VERSION ""

NS_ :

BS_:

BU_: GNSSReceiver
VAL_TABLE_ evPgn 129029 "GNSS Position Data" 129025 "Position Rapid Update" ;

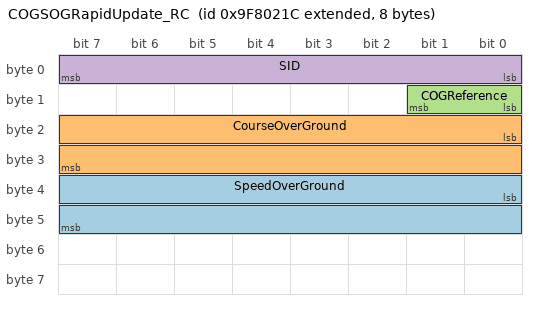
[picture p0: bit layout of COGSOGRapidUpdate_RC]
BO_ 2314732060 COGSOGRapidUpdate_RC: 8 GNSSReceiver
 SG_ SpeedOverGround : 32|16@1+ (0.01,0) [0|655.32] "m/s" Vector__XXX
 SG_ CourseOverGround : 16|16@1+ (0.0001,0) [0|6.28318] "rad" Vector__XXX
 SG_ COGReference : 8|2@1+ (1,0) [0|3] "" Vector__XXX
 SG_ SID : 0|8@1+ (1,0) [0|252] "" Vector__XXX

BO_ 2314731804 GNSSPositionRapidUpdate_RC: 8 GNSSReceiver
 SG_ Latitude : 0|32@1- (1E-007,0) [-90|90] "deg" Vector__XXX
 SG_ Longitude : 32|32@1- (1E-007,0) [-180|180] "deg" Vector__XXX

BO_ 2583168284 GNSSPositionData_RC: 47 GNSSReceiver
 SG_ SequenceID : 0|8@1+ (1,0) [0|255] "" Vector__XXX
 SG_ PositionDate : 8|16@1+ (1,0) [0|65532] "day" Vector__XXX
 SG_ PositionTime : 24|32@1+ (0.0001,0) [0|86401] "s" Vector__XXX
 SG_ Latitude : 56|64@1+ (1E-016,0) [-90|90] "deg" Vector__XXX
 SG_ Longitude : 120|64@1- (1E-016,0) [-180|180] "deg" Vector__XXX
 SG_ Altitude : 184|64@1- (1E-006,0) [-9223372036854.78|9223372036854.78] "m" Vector__XXX
 SG_ TypeOfSystem : 248|4@1+ (1,0) [0|4] "" Vector__XXX
 SG_ GNSSMethod : 252|4@1+ (1,0) [0|15] "" Vector__XXX
 SG_ GNSSIntegrity : 256|2@1+ (1,0) [0|3] "" Vector__XXX
 SG_ NumberOfSVs : 264|8@1+ (1,0) [0|252] "" Vector__XXX
 SG_ HDOP : 272|16@1- (0.01,0) [-327.64|327.64] "" Vector__XXX
 SG_ PDOP : 288|16@1- (0.01,0) [-327.64|327.64] "" Vector__XXX
 SG_ GeoidalSeparation : 304|32@1- (0.01,0) [-21470000|21470000] "m" Vector__XXX
 SG_ NumberOfReferenceStations : 336|8@1+ (1,0) [0|252] "" Vector__XXX
 SG_ RefrenceStationType1 : 344|4@1+ (1,0) [0|15] "" Vector__XXX
 SG_ ReferenceStationID1 : 348|12@1+ (1,0) [0|4095] "" Vector__XXX
 SG_ AgeOfDGNSSCorrections1 : 360|16@1+ (0.01,0) [0|655.32] "sec" Vector__XXX

BO_ 2565799452 ACL_RC: 8 GNSSReceiver
 SG_ IdentityNumber : 0|21@1+ (1,0) [0|2097150] "" Vector__XXX
 SG_ ManufacturerCode : 21|11@1+ (1,0) [0|2047] "" Vector__XXX
 SG_ ECUInstance : 32|3@1+ (1,0) [0|7] "" Vector__XXX
 SG_ FunctionInstance : 35|5@1+ (1,0) [0|31] "" Vector__XXX
 SG_ Function : 40|8@1+ (1,0) [0|255] "" Vector__XXX
 SG_ VehicleSystem1 m1 : 49|7@1+ (1,0) [0|127] "" Vector__XXX
 SG_ VehicleSystem2 m2 : 49|7@1+ (1,0) [0|127] "" Vector__XXX
 SG_ VehicleSystem3 m3 : 49|7@1+ (1,0) [0|127] "" Vector__XXX
 SG_ VehicleSystem4 m4 : 49|7@1+ (1,0) [0|127] "" Vector__XXX
 SG_ VehicleSystem5 m5 : 49|7@1+ (1,0) [0|127] "" Vector__XXX
 SG_ VehicleSystem m0 : 49|7@1+ (1,0) [0|127] "" Vector__XXX
 SG_ VehicleSystemInstance : 56|4@1+ (1,0) [0|15] "" Vector__XXX
 SG_ IndustryGroup M : 60|3@1+ (1,0) [0|7] "" Vector__XXX
 SG_ ArbitraryAddressCapable : 63|1@1+ (1,0) [0|1] "" Vector__XXX

BO_ 2565406236 ACKM_RC: 8 GNSSReceiver
 SG_ ControlByte M : 0|8@1+ (1,0) [0|0] "" Vector__XXX
 SG_ GroupFunctionValue : 8|8@1+ (1,0) [0|0] "" Vector__XXX
 SG_ AddressAcknowledged m0 : 32|8@1+ (1,0) [0|0] "" Vector__XXX
 SG_ AddressNegativeAcknowledgement m1 : 32|8@1+ (1,0) [0|0] "" Vector__XXX
 SG_ AddressAccessDenied m2 : 32|8@1+ (1,0) [0|0] "" Vector__XXX
 SG_ AddressBusy m3 : 32|8@1+ (1,0) [0|0] "" Vector__XXX
 SG_ ParameterGroupNumber : 40|24@1+ (1,0) [0|0] "" Vector__XXX

EV_ evDataNumOfRefStat: 0 [0|252] "" 0 1 DUMMY_NODE_VECTOR0 Vector__XXX;

EV_ evCmdOpenGNSSPosDataValues: 0 [0|1] "" 0 2 DUMMY_NODE_VECTOR0 Vector__XXX;

EV_ evDataGeoSeparation: 0 [-21470000|21470000] "" 0 3 DUMMY_NODE_VECTOR0 Vector__XXX;

EV_ evDataPDOP: 0 [-32764|32764] "" 0 4 DUMMY_NODE_VECTOR0 Vector__XXX;

EV_ evDataHDOP: 0 [-32764|32764] "" 0 5 DUMMY_NODE_VECTOR0 Vector__XXX;

EV_ evDataNumOfSVs: 0 [0|252] "" 0 6 DUMMY_NODE_VECTOR0 Vector__XXX;

EV_ evDataIntegrity: 0 [0|3] "" 0 7 DUMMY_NODE_VECTOR0 Vector__XXX;

EV_ evDataSysAndMethod: 0 [0|255] "" 0 8 DUMMY_NODE_VECTOR0 Vector__XXX;

EV_ evDataFixId: 0 [0|1] "" 0 9 DUMMY_NODE_VECTOR0 Vector__XXX;

EV_ evCmdSetGNSSPosDataValues: 0 [0|1] "" 0 10 DUMMY_NODE_VECTOR0 Vector__XXX;

EV_ evCmdContinueSpeed: 0 [0|1] "" 0 11 DUMMY_NODE_VECTOR0 Vector__XXX;

EV_ evSpeedNew: 1 [0|0] "" 0 12 DUMMY_NODE_VECTOR0 Vector__XXX;

EV_ evAddSpeed: 0 [0|1] "" 0 13 DUMMY_NODE_VECTOR0 Vector__XXX;

EV_ evCmdRemoveWPs: 0 [0|1] "" 0 14 DUMMY_NODE_VECTOR0 Vector__XXX;

EV_ evPGEnable: 0 [0|1] "" 0 15 DUMMY_NODE_VECTOR0 Vector__XXX;

EV_ evCmdSetPGSettings: 0 [0|1] "" 0 16 DUMMY_NODE_VECTOR0 Vector__XXX;

EV_ evPGN: 0 [0|0] "" 129029 17 DUMMY_NODE_VECTOR0 Vector__XXX;

EV_ evPGPriority: 0 [0|7] "" 3 18 DUMMY_NODE_VECTOR0 Vector__XXX;

EV_ evPGUpateRate: 0 [50|100000] "" 1000 19 DUMMY_NODE_VECTOR0 Vector__XXX;

EV_ evJitterAtl: 1 [0|3.4E+038] "" 0 20 DUMMY_NODE_VECTOR0 Vector__XXX;

EV_ evJitterLonLat: 1 [0|3.4E+038] "" 0 21 DUMMY_NODE_VECTOR0 Vector__XXX;

EV_ evCmdPauseSpeed: 0 [0|1] "" 0 22 DUMMY_NODE_VECTOR0 Vector__XXX;

EV_ evSimulationState: 0 [0|2] "" 0 23 DUMMY_NODE_VECTOR0 Vector__XXX;

EV_ evSpeed: 1 [0|1000] "" 0 24 DUMMY_NODE_VECTOR0 Vector__XXX;

EV_ evCmdStopReplay: 0 [0|1] "" 0 25 DUMMY_NODE_VECTOR0 Vector__XXX;

EV_ evCmdStartReplay: 0 [0|1] "" 0 26 DUMMY_NODE_VECTOR0 Vector__XXX;

EV_ evReferenceType: 0 [0|1] "" 0 27 DUMMY_NODE_VECTOR0 Vector__XXX;

EV_ evLengthAltitude: 1 [-3.4E+038|3.4E+038] "" 0 28 DUMMY_NODE_VECTOR0 Vector__XXX;

EV_ evLengthLongitude: 1 [-3.4E+038|3.4E+038] "" 0 29 DUMMY_NODE_VECTOR0 Vector__XXX;

EV_ evLengthLatitude: 1 [-3.4E+038|3.4E+038] "" 0 30 DUMMY_NODE_VECTOR0 Vector__XXX;

EV_ evCmdAddRefPoint: 0 [0|1] "" 0 31 DUMMY_NODE_VECTOR0 Vector__XXX;

EV_ evCmdAddNewPointRef: 0 [0|1] "" 0 32 DUMMY_NODE_VECTOR0 Vector__XXX;

EV_ evCmdAddNewPoint: 0 [0|1] "" 0 33 DUMMY_NODE_VECTOR0 Vector__XXX;

EV_ evAltitudeNew: 1 [-3.4E+038|3.4E+038] "" 0 34 DUMMY_NODE_VECTOR0 Vector__XXX;

EV_ evLongitudeNew: 1 [-180|180] "" 0 35 DUMMY_NODE_VECTOR0 Vector__XXX;

EV_ evLatitudeNew: 1 [-90|90] "" 0 36 DUMMY_NODE_VECTOR0 Vector__XXX;

EV_ evAltitudeRef: 1 [-3.4E+038|3.4E+038] "" 0 37 DUMMY_NODE_VECTOR0 Vector__XXX;

EV_ evLongitudeRef: 1 [-180|180] "" 0 38 DUMMY_NODE_VECTOR0 Vector__XXX;

EV_ evLatitudeRef: 1 [-90|90] "" 0 39 DUMMY_NODE_VECTOR0 Vector__XXX;

CM_ BO_ 2314732060 "This PGN is a single frame PGN that provides Course Over Ground(COG)and Speed Over Ground(SOG).

Being a single frame Msg,as opposed to other PGNs that include COG and SOG and are defined as multi-packet,this PGN lends itself to being transmitted more f";
CM_ SG_ 2314732060 CourseOverGround "The direction of the path over ground actually followed by a vessel.";
CM_ SG_ 2314732060 COGReference "0 = True, 
1 = Magnetic, 
2 = Error, 
3 = Null";
CM_ SG_ 2314732060 SID "An upward counting number used to tie related information together between different PGNs.For example,SID would be used to tie together COG,SOG and RAIM values to a given Pos.255=no valid Pos fix to tie it to.Range 0 to 250 for valid Pos fixes.";
CM_ BO_ 2314731804 "This PGN provides latitude and longitude referenced to WGS84";
CM_ BO_ 2583168284 "This PGN conveys a comprehensive set of Global Navigation Satellite System (GNSS) parameters, including position 
information
";
CM_ SG_ 2583168284 SequenceID "An upward counting number used to tie related information together between different PGNs.
";
CM_ SG_ 2583168284 PositionDate "Days since January 1, 1970,  Date is relative to UTC Time";
CM_ SG_ 2583168284 PositionTime "24 hour clock, 0 =  midnight,  time is in UTC";
CM_ SG_ 2583168284 Latitude "Latitude referenced to WGS-84";
CM_ SG_ 2583168284 Longitude "Longitude referenced to WGS-84";
CM_ SG_ 2583168284 Altitude "Altitude referenced to WGS-84";
CM_ SG_ 2583168284 NumberOfSVs "Numeric count, event counter, sequence counter";
CM_ SG_ 2583168284 HDOP "Dilution of Precision (DOP) indicates the contribution of satellite configuration geometry to positioning error
";
CM_ SG_ 2583168284 PDOP "Dilution of Precision (DOP) indicates the contribution of satellite configuration geometry to positioning error
";
CM_ SG_ 2583168284 GeoidalSeparation "The difference between the earth ellipsoid and mean-sea-level (geoid) defined by the reference datum used in the position solution ' -' = mean-sea-level below ellipsoid
";
CM_ SG_ 2583168284 NumberOfReferenceStations "Numeric count, event counter, sequence counter";
CM_ SG_ 2583168284 ReferenceStationID1 "Reference Station ID";
CM_ SG_ 2583168284 AgeOfDGNSSCorrections1 "Age of Differential corrections";
CM_ BO_ 2565799452 "Address Claimed";
CM_ BO_ 2565406236 "Acknowledge";
BA_DEF_ SG_  "SPN" INT 0 524287;
BA_DEF_ SG_  "SigType" ENUM  "Default","Range","RangeSigned","ASCII","Discrete","Control","ReferencePGN","DTC","StringDelimiter","StringLength","StringLengthControl";
BA_DEF_ BO_  "SingleFrame" INT 0 1;
BA_DEF_ BO_  "VFrameFormat" ENUM  "StandardCAN","ExtendedCAN","reserved","J1939PG","vector_leerstring";
BA_DEF_ BO_  "GenMsgSendType" ENUM  "cyclic","reserved","cyclicIfActive","reserved","reserved","reserved","reserved","reserved","noMsgSendType","vector_leerstring";
BA_DEF_ BO_  "GenMsgCycleTime" INT 0 3600000;
BA_DEF_ BO_  "GenMsgRequestable" INT 0 1;
BA_DEF_  "ProtocolType" STRING ;
BA_DEF_  "BusType" STRING ;
BA_DEF_ BU_  "COGSOGRapidUpdate_SequenceID" INT 0 255;
BA_DEF_ BU_  "COGSOGRapidUpdate_CogRef" INT 0 3;
BA_DEF_ BU_  "GNSSPosData_AgeOfDGNSSRefStat2" FLOAT 0 655.32;
BA_DEF_ BU_  "GNSSPosData_RefStationID2" INT 0 65535;
BA_DEF_ BU_  "GNSSPosData_RefStationType2" INT 0 15;
BA_DEF_ BU_  "GNSSPosData_SequenceID" INT 0 252;
BA_DEF_ BU_  "GNSSPosData_AgeOfDGNSSRefStat1" FLOAT 0 655.32;
BA_DEF_ BU_  "GNSSPosData_RefStationID1" INT 0 65535;
BA_DEF_ BU_  "GNSSPosData_RefStationType1" INT 0 15;
BA_DEF_ BU_  "GNSSPosData_NumOfRefStations" INT 0 252;
BA_DEF_ BU_  "GNSSPosData_GeodialSeparation" FLOAT -21470000 21470000;
BA_DEF_ BU_  "GNSSPosData_PDOP" FLOAT -327.64 327.64;
BA_DEF_ BU_  "GNSSPosData_HDOP" FLOAT -327.64 327.64;
BA_DEF_ BU_  "GNSSPosData_NumberOfSVs" INT 0 252;
BA_DEF_ BU_  "GNSSPosData_GNSSIntegrity" INT 0 3;
BA_DEF_ BU_  "GNSSPosData_MethodGNSS" INT 0 15;
BA_DEF_ BU_  "GNSSPosData_TypeOfSystem" INT 0 4;
BA_DEF_ BU_  "NmStationAddress" INT 0 254;
BA_DEF_ BU_  "NodeLayerModules" STRING ;
BA_DEF_ BU_  "NmJ1939AAC" INT 0 1;
BA_DEF_ BU_  "NmJ1939IndustryGroup" INT 0 7;
BA_DEF_ BU_  "NmJ1939SystemInstance" INT 0 15;
BA_DEF_ BU_  "NmJ1939System" INT 0 127;
BA_DEF_ BU_  "NmJ1939Function" INT 0 255;
BA_DEF_ BU_  "NmJ1939FunctionInstance" INT 0 31;
BA_DEF_ BU_  "NmJ1939ECUInstance" INT 0 7;
BA_DEF_ BU_  "NmJ1939ManufacturerCode" INT 0 2047;
BA_DEF_ BU_  "J1939Name" STRING ;
BA_DEF_ BU_  "NmJ1939IdentityNumber" INT 0 2097151;
BA_DEF_DEF_  "SPN" 0;
BA_DEF_DEF_  "SigType" "Default";
BA_DEF_DEF_  "SingleFrame" 1;
BA_DEF_DEF_  "VFrameFormat" "J1939PG";
BA_DEF_DEF_  "GenMsgSendType" "noMsgSendType";
BA_DEF_DEF_  "GenMsgCycleTime" 0;
BA_DEF_DEF_  "GenMsgRequestable" 1;
BA_DEF_DEF_  "ProtocolType" "";
BA_DEF_DEF_  "BusType" "";
BA_DEF_DEF_  "COGSOGRapidUpdate_SequenceID" 0;
BA_DEF_DEF_  "COGSOGRapidUpdate_CogRef" 0;
BA_DEF_DEF_  "GNSSPosData_AgeOfDGNSSRefStat2" 0;
BA_DEF_DEF_  "GNSSPosData_RefStationID2" 0;
BA_DEF_DEF_  "GNSSPosData_RefStationType2" 0;
BA_DEF_DEF_  "GNSSPosData_SequenceID" 0;
BA_DEF_DEF_  "GNSSPosData_AgeOfDGNSSRefStat1" 0;
BA_DEF_DEF_  "GNSSPosData_RefStationID1" 0;
BA_DEF_DEF_  "GNSSPosData_RefStationType1" 0;
BA_DEF_DEF_  "GNSSPosData_NumOfRefStations" 0;
BA_DEF_DEF_  "GNSSPosData_GeodialSeparation" 0;
BA_DEF_DEF_  "GNSSPosData_PDOP" 0;
BA_DEF_DEF_  "GNSSPosData_HDOP" 0;
BA_DEF_DEF_  "GNSSPosData_NumberOfSVs" 0;
BA_DEF_DEF_  "GNSSPosData_GNSSIntegrity" 0;
BA_DEF_DEF_  "GNSSPosData_MethodGNSS" 0;
BA_DEF_DEF_  "GNSSPosData_TypeOfSystem" 0;
BA_DEF_DEF_  "NmStationAddress" 254;
BA_DEF_DEF_  "NodeLayerModules" "GNSS_NL.dll";
BA_DEF_DEF_  "NmJ1939AAC" 0;
BA_DEF_DEF_  "NmJ1939IndustryGroup" 0;
BA_DEF_DEF_  "NmJ1939SystemInstance" 0;
BA_DEF_DEF_  "NmJ1939System" 0;
BA_DEF_DEF_  "NmJ1939Function" 0;
BA_DEF_DEF_  "NmJ1939FunctionInstance" 0;
BA_DEF_DEF_  "NmJ1939ECUInstance" 0;
BA_DEF_DEF_  "NmJ1939ManufacturerCode" 0;
BA_DEF_DEF_  "J1939Name" "(null)";
BA_DEF_DEF_  "NmJ1939IdentityNumber" 0;
BA_ "BusType" "CAN";
BA_ "ProtocolType" "ISO11783";
BA_ "J1939Name" BU_ GNSSReceiver "GNSSReceiver";
BA_ "NmJ1939Function" BU_ GNSSReceiver 23;
BA_ "NmJ1939IndustryGroup" BU_ GNSSReceiver 2;
BA_ "NmJ1939AAC" BU_ GNSSReceiver 1;
BA_ "NmStationAddress" BU_ GNSSReceiver 28;
BA_ "GenMsgCycleTime" BO_ 2314732060 250;
BA_ "GenMsgCycleTime" BO_ 2314731804 100;
BA_ "GenMsgSendType" BO_ 2314731804 8.51951780093012E-317;
BA_ "GenMsgCycleTime" BO_ 2583168284 100;
BA_ "GenMsgSendType" BO_ 2583168284 8.52390115134002E-317;
BA_ "SingleFrame" BO_ 2583168284 0;
BA_ "SigType" SG_ 2314732060 SpeedOverGround 1;
BA_ "SigType" SG_ 2314732060 CourseOverGround 1;
BA_ "SigType" SG_ 2314732060 COGReference 4;
BA_ "SigType" SG_ 2314732060 SID 1;
BA_ "SigType" SG_ 2583168284 SequenceID 1;
BA_ "SigType" SG_ 2583168284 PositionDate 1;
BA_ "SigType" SG_ 2583168284 PositionTime 1;
BA_ "SigType" SG_ 2583168284 Latitude 1;
BA_ "SigType" SG_ 2583168284 GNSSIntegrity 4;
BA_ "SigType" SG_ 2583168284 NumberOfSVs 1;
BA_ "SigType" SG_ 2583168284 NumberOfReferenceStations 1;
BA_ "SigType" SG_ 2583168284 ReferenceStationID1 1;
BA_ "SigType" SG_ 2583168284 AgeOfDGNSSCorrections1 1;
BA_ "SigType" SG_ 2565799452 IdentityNumber 1;
BA_ "SigType" SG_ 2565799452 ManufacturerCode 1;
BA_ "SigType" SG_ 2565799452 Function 1;
BA_ "SPN" SG_ 2565406236 ControlByte 2541;
BA_ "SPN" SG_ 2565406236 GroupFunctionValue 2542;
BA_ "SPN" SG_ 2565406236 ParameterGroupNumber 2574;
VAL_ 2314732060 COGReference 3 "Null" 2 "Error" 1 "Magnetic" 0 "True" ;
VAL_ 2314732060 SID 255 "nVldPsFxTTItTRng0T250FrVldPstnFx" ;
VAL_ 2583168284 TypeOfSystem 0 "GPS" 1 "GLONASS" 2 "GPS and GLONASS" 3 "GPS and SBAS(WAAS)" 4 "GPS and SBAS and GLONASS" ;
VAL_ 2583168284 GNSSMethod 0 "no GPS" 1 "GNSS fix" 2 "DGNSS fix" 3 "Precise GNSS" 4 "RTK fixed integer" 5 "RTK float" 6 "Estimated (DR) mode" 7 "Manual input" 8 "Simulate mode" 14 "Error" ;
VAL_ 2583168284 GNSSIntegrity 0 "No integrity checking" 1 "Safe" 2 "Caution" 3 "Unsafe" ;
VAL_ 2583168284 RefrenceStationType1 0 "GPS" 1 "GLONASS" 14 "Error" ;
VAL_ 2565799452 ManufacturerCode 381 "B&G" 374 "Northern Lights" 373 "Electronic Design" 371 "Delphi" 370 "Heinzmann GmbH & Co. KG" 369 "Power Torque Engineering Ltd" 368 "HANSENHOF_electronic" 367 "Fliegl Agrartechnik" 366 "Viewnyx Corp." 365 "Digi-Star, LLC" 364 "OEM Controls Inc." 363 "BEI Duncan" 362 "Alois Poettinger Maschinenfabrik" 361 "InMach" 360 "HJS Fahrzeugtechnik GmbH & Co KG" 359 "Ludwig Bergmann GmbH" 358 "Victron Energy BV" 357 "Hardi International A/S" 356 "Fischer Panda Generators, Inc" 355 "Mastervolt International B.V." 354 "Junkkari OY" 353 "Hegemon Electronics, Inc." 352 "SAME DEUTZ-FAHR" 351 "Thrane & Thrane" 350 "Noris Marine Systems GmbH & Co" 349 "Suonentieto" 348 "Amazonen Werke H. Dreyer" 347 "Honeywell" 346 "Control Solutions" 345 "Korean Maritime University" 344 "Parvus Corporation" 343 "Baumer Group" 342 "THOMAS MAGNETE GmbH" 341 "Boning GmbH & Co" 340 "Continental AG" 339 "Competence Center ISOBUS e.V." 338 "GRAF-SYTECO" 337 "Carraro S.p.A" 336 "APE s.r.o." 335 "Evo Electric Ltd" 334 "Takata-Petri AG" 333 "Hadley Products Corporation" 332 "HWH Corporation" 331 "Horton, Inc." 330 "Kidde Aerospace and Defense" 329 "Deif A/S" 328 "Qwerty Electronik AB" 252 "Sensor-Technik Wiedemann GmbH" 251 "German Agricultural Society" 250 "Kuhn Group" 249 "Schaltbau GmbH" 233 "Yacht Monitoring Solutions Inc." 232 "TSD Integrated Controls" 1863 "Thomas G. Faria Co." 1862 "Sanshin" 1861 "Vector North America" 1860 "MMP" 1859 "Kvasar AB" 1858 "Litton" 1857 "Simrad" 1856 "Trimble" 1855 "Furuno USA" 1854 "Northstar Technologies" 1853 "Japan Radio Co." 1852 "Navionics" 1851 "Raymarine" 1850 "Teleflex" 222 "Generac Power Systems, Inc." 221 "SiE" 220 "Beede Electrical Instrument Company, Inc." 219 "Cat OEM Solutions" 218 "Gits Manufacturing Company" 217 "RM Michaelides Software & Elektronik GmbH" 216 "Paneltronics Inc." 215 "Aetna Engineering/Fireboy-Xintex" 214 "MC elettronica Srl" 213 "CNH Belgium N.V." 212 "Sure Power Industries, Inc." 211 "DNA Group" 210 "Iteris, Inc." 209 "Bell Equip. Co. SA (PTY) LTD" 208 "Drew Technologies, Inc." 207 "Otto Engineering" 206 "port GmbH" 205 "SmarTire Systems Inc" 204 "The Morey Corporation" 203 "MILtronik GmbH" 202 "Curtis Instruments, Inc." 201 "Disenos y Tecnologia S.A." 200 "MGM Brakes" 199 "Actia Corp." 198 "Mystic Valley Communications" 197 "Mechron Power Systems" 196 "LEMKEN GmbH & Co. KG" 195 "General Engine Products" 194 "TriMark Corporation" 193 "Jeppesen Marine" 192 "Floscan" 191 "XATA Corporation" 190 "Hella KGaA Hueck & Co." 189 "QUALCOMM" 188 "EMP Corp." 187 "Air-Weigh" 186 "Altronic, Inc." 185 "Beede Electrical Instrument Company" 184 "EIA Electronics" 183 "KDS Controls, Inc." 182 "Vehicle Systems Engineering B.V." 181 "Coretronics, Inc." 180 "Smart Power Systems" 179 "TeeJet Technologies Denmark" 178 "Siemens VDO Automotive AG" 177 "Diagnostic System Associates" 176 "Moritz Aerospace" 175 "Veris Technologies, Inc." 174 "AB Volvo Penta" 173 "Ryeso, Inc." 172 "Yanmar Marine USA" 171 "Wachendorff Elektronik GmbH & Co. KG" 170 "Computronics Corporation Ltd." 169 "Marlin Technologies Inc." 168 "Xantrex" 167 "JLG Industries Inc." 166 "Phoenix International" 165 "CPAC Systems AB" 164 "DaimlerChrysler Off-Highway" 163 "BRP Inc." 162 "Axiomatic Technologies" 161 "Offshore Systems (UK) Limited" 160 "Nido" 159 "NTech Industries Inc." 158 "Firestone Industrial Products Company" 157 "ISSPRO Inc." 156 "ITT Industries - Cannon" 155 "Vetronix Corporation" 154 "Westerbeke Corporation" 153 "Woodward, Industrial Controls Division" 152 "Elobau Elektrobauelemente GmbH & Co. KG" 151 "Raven Industries Inc. - Flow Controls Division" 150 "Fleetguard" 149 "Holset" 148 "Blue Water Data, Inc." 147 "Nautibus Electronic GmbH" 146 "Maxima Technologies" 145 "MurCal Controls" 144 "Mercury Marine" 143 "W. Gmeiner GmbH & Co." 142 "TRW Automotive (Commercial Steering Systems)" 141 "Thales Navigation Ltd." 140 "Lowrance Electronics, Inc." 139 "Caterpillar Trimble Control Technologies (CTCT), LLC" 138 "Georg Fritzmeier GmbH & Co. KG" 137 "Maretron" 136 "Komatsu Ltd." 135 "Airmar Technology Corporation" 134 "Iris Technology Ltd." 133 "Bucher Schoerling GmbH" 132 "Mulag-Fahrzeugwerk" 131 "ITT Industries" 130 "Nido - Universal Machines B.V." 129 "OMNEX Control Systems, Inc." 128 "Gerhard Duecker GmbH & Co. KG" 127 "Holland USA" 126 "Driver Tech" 125 "Nevada Automotive Test Center" 124 "Hydac Electronic" 123 "Basler Electric" 122 "FG Wilson (Engineering) Limited" 121 "HED (Hydro Electronic Devices, Inc.)" 120 "RDS Technology Ltd." 119 "IntegriNautics" 118 "Intron GmbH" 117 "HUSCO International" 116 "BEELINE Technologies" 115 "NACCO Materials Handling Group, Inc." 114 "EControls, Inc." 113 "Stress-Tek, Inc." 112 "MECALAC" 111 "Maschinenfabrik Bernhard Krone GmbH" 110 "EPIQ Sensor-Nite" 109 "TeeJet Technologies Denmark" 108 "WTK-Elecktronik GmbH" 107 "Grimme Landmaschinen GmbH & Co. KG" 106 "BAE Systems Controls, Inc." 105 "Kiepe Elektrik GmbH & Co. KG" 104 "Claas Selbstfahrende Erntemaschinen GmbH" 103 "Agrocom GmbH & Co. Agrarsystem KG" 102 "AGCO GmbH & Co." 101 "Sensoria" 100 "VDO Technik AG" 99 "International Transmissions Ltd (ITL)" 98 "Mueller-Elektronik GmbH & Co." 97 "Ag Leader Technology, Inc." 96 "Mech@tronic IT GmbH" 95 "Pacific Insight Electronics Corp." 94 "CNH Global N.V." 93 "Perkins Engines Company Ltd." 92 "Ag-Chem Equipment Co., Inc." 91 "BSG Bodensee Steuergeraete GmbH" 90 "Knorr-Bremse SfN GmbH" 89 "Kverneland Group, Electronics Division" 88 "Satloc Precision GPS" 87 "J.C. Bamford Excavators Ltd (JCB)" 86 "C.E. Niehoff & Company" 85 "Kohler Co." 84 "New Holland UK Limited" 83 "Eaton VORAD Technologies" 82 "Bobcat/Ingersoll-Rand" 81 "Fire Research Corp" 80 "Twin Disc, Inc." 79 "Daimler Benz AG - Engine Division (PBM)" 78 "Frank W. Murphy Manufacturing, Inc." 77 "Deere Power Systems Group" 76 "unused" 75 "Deere & Co. Agricultural Division" 74 "Eaton Axle-Brake Division" 73 "LeTourneau, Inc." 72 "Sisu Corporation" 71 "Vansco Electronics Ltd." 70 "Flex-Coil Limited" 69 "Trimble Navigation" 68 "Scania" 67 "Funk Manufacturing Company" 66 "John Deere Construction Equipment Division" 65 "MAN Nutzfahrzeuge AG" 64 "unused" 63 "ZF Industries Inc." 62 "Wabco" 61 "Volvo Truck Corp." 60 "Volvo Trucks North America Inc." 59 "VES Inc." 58 "SPX Corporation, OTC Division" 57 "Sauer-Danfoss Co." 56 "SAIC" 55 "Ryder System Inc." 54 "Meritor Wabco" 53 "Continental Automotive Systems US, Inc." 52 "Meritor Automotive, Inc." 51 "Robert Bosch GmbH" 50 "Robert Bosch Corp" 49 "RE America Inc." 48 "Pollak Alphabet" 47 "Phillips Semiconductor" 46 "Parasoft Computing Solutions" 45 "PACCAR" 44 "Nippondenso Co. Ltd." 43 "International Truck and Engine Corp. Vehicle Electronics" 42 "International Truck and Engine Corp. Engine Electronics" 41 "Motorola Inc." 40 "Motorola AIEG Inc." 39 "Microfirm Inc." 38 "Micro Processor Systems Inc." 37 "Mack Trucks Inc." 36 "Lucas Ltd." 35 "Kenworth Truck Co." 34 "Kelsey Hayes Co." 33 "John Deere" 32 "Jacobs Vehicle Systems" 31 "J Pollak Corp." 30 "Isuzu Motors Ltd." 29 "Hino Motors Ltd." 28 "Grote Ind. Inc." 27 "GMC" 26 "General Motors Corp., Service Technology Group" 25 "Daimler Trucks North America LLC" 24 "Ford Motor Co., Vehicle Controls" 23 "Ford Motor Co., Heavy Truck" 22 "Ford Motor Co., Electronic Concepts $ Systems" 21 "Echilin Inc., Midland Brake Inc." 20 "Eaton Ltd" 19 "Eaton Corp. Trucking Info Services" 18 "Eaton Corp, Transmission Division" 17 "Eaton Corp. Res & Dev" 16 "Eaton Corp." 15 "Dickey-John Corp." 14 "Detroit Diesel Corporation" 13 "Delco Electronics" 12 "Deere & Company, Precision Farming" 11 "Dearborn Group Inc." 10 "Cummins Engine Co." 9 "Chrysler Corp." 8 "Caterpillar Inc." 7 "Case Corp." 6 "Berifors Electronics AB" 5 "AMP Inc." 4 "Ametek-Dixson" 3 "Ametek, US Gauge Division" 2 "Allison Transmission, GMC" 1 "Allied Signal Inc." 0 "Reserved" 231 "Topcon Positioning Systems, Inc." 230 "Saucon Technologies" 229 "Garmin International Inc." 228 "ZF Marine Electronics" 227 "Lykketronic A/S" 226 "Monaco Coach Corporation" 225 "SKF" 224 "EMMI Network, S.L." 223 "Vaueo Retarder Co., Ltd." 263 "IMMI" 262 "HydraForce, Inc" 261 "Red Dot Corporation" 260 "Reichhardt GmbH" 259 "Jetter AG" 258 "ARAG" 257 "Honda Motor Co., Ltd" 256 "Tyco Electronics AMP" 255 "MEAS France" 254 "GE Sensing" 253 "Mobile Control Systems" 298 "Holley Performance" 297 "Zonar Systems Inc" 296 "micro dynamics GmbH" 295 "BEP Marine" 294 "Grayhill Inc." 293 "Spyder Controls Corp." 292 "IKUSI - Angel Iglesias S.A." 291 "Groeneveld Transport Efficiency BV" 290 "Kuebler GmbH" 289 "Watlow" 288 "Mitsubishi FUSO Truck & Bus Corp." 287 "NTech Industries, Inc" 286 "Coelmo srl" 285 "Sea Recovery Corp" 284 "Mobile Tech Chile" 283 "CWF Hamilton & Co Ltd" 282 "Medallion Instrumentation Systems" 281 "Precision Governors LLC" 311 "Patrick Power Products" 310 "TECNORD srl" 309 "Krauss-Maffei Wegmann GmbH & Co. KG" 308 "Cyntrx" 307 "MAS Technologies" 306 "Sleipner Motor AB" 305 "NovAtel Inc" 304 "EmpirBus AB" 303 "CTS Corporation" 302 "Nissin Kogyo Co., LTD" 301 "Parker Hannifin (UK) Ltd FDE group" 300 "Systron Donner Automotive" 299 "Rauch Landmaschinen GmbH" 280 "Leica Geosystems Pty Ltd" 279 "Geometris LP" 278 "Takata Electronics" 277 "LHP Telematics" 276 "Aqua-Hot Heating Systems" 275 "Navico Egersund AS" 274 "LTW Technology Co., LTD" 273 "Active Research Limited" 272 "Gross Mechanical Laboratories, Inc" 327 "Sonceboz SA" 326 "Akron Brass Company" 325 "ASM Automation Sensorik Messtechnik GmbH" 324 "Snap-on Diagnostics" 323 "Mobileye Vision Technologies Ltd." 322 "MICHENKA s.r.o." 321 "Ultra Electronics, Electrics" 320 "Miedema Landbouwwerktuigenfabriek B.V." 319 "Cadec Global" 318 "SAT Plan" 317 "Navtronics Bvba" 316 "ITT Flow Control" 315 "Icom Incorporated" 314 "CSM GmbH" 313 "Ilmor Engineering, Inc" 312 "Lectronix, Inc." 271 "Cole Hersee" 270 "Tennant" 269 "Saft America Inc.,  Space & Defense Division" 268 "Accurate Technologies" 267 "Red Lion Controls, Inc" 266 "International Thermal Research Ltd" 265 "MTS Sensor Technologie GmbH" 264 "Autolync" 248 "Cooper Standard Automotive Active Systems Group" 247 "ePULSE" 246 "Class 1, Inc" 245 "Capstan Ag Systems, Inc." 244 "Techno-Matic" 243 "eRide, Inc." 242 "Kokusandenki Co. Ltd" 241 "Schneider Automation SAS " 240 "Vanair Mfg" 239 "May & Scofield Ltd" 238 "ZF Friedrichshafen AG" 237 "Agtron Enterprises Inc" 236 "Norac Systems International Inc" 235 "SailorMade Marine Telemetry - Tetra Technology Ltd." 234 "Mondial electronic GmbH" ;
VAL_ 2565799452 Function 127 "Reserved" 126 "Reserved" 125 "Reserved" 124 "Reserved" 123 "Reserved" 122 "Reserved" 121 "Reserved" 120 "Reserved" 119 "Reserved" 118 "Reserved" 117 "Reserved" 116 "Reserved" 115 "Reserved" 114 "Reserved" 113 "Reserved" 112 "Reserved" 111 "Reserved" 110 "Reserved" 109 "Reserved" 108 "Reserved" 107 "Reserved" 106 "Reserved" 105 "Reserved" 104 "Reserved" 103 "Reserved" 102 "Reserved" 101 "Reserved" 42 "Water Pump Control" 41 "Lighting - Operator Controls" 40 "Seat Control" 39 "Ignition Control Module" 38 "Tire Pressure Control" 37 "Cab Controller" 36 "Pneumatic - System Controller" 35 "Suspension - System Controller" 34 "Hydraulic Pump Controller" 33 "System Monitor" 32 "Headway Controller" 31 "Propulsion Battery Charger" 30 "Management Computer" 29 "Virtual Terminal (In Cab)" 28 "Off Vehicle Gateway" 27 "Power TakeOff (Secondary or Front)" 26 "Body Controller" 25 "Network Interconnect ECU" 24 "Vehicle Security" 23 "Vehicle Navigation" 22 "Aerodynamic Control" 21 "Cab Climate Control" 20 "Trip Recorder" 19 "Instrument Cluster" 18 "Suspension - Drive Axle" 17 "Suspension - Steer Axle" 16 "Steeting Controller" 15 "Fuel System" 14 "Cruise Control" 13 "Retarder - Driveline" 12 "Retarder - Engine" 11 "Brakes - Drive Axle" 10 "Brakes - Steer Axle" 9 "Brakes - System Controller" 8 "Axle - Drive" 7 "Axle - Steering" 6 "Power TakeOff - (Main or Rear)" 5 "Shift Control/Console" 4 "Battery Pack Monitor" 3 "Transmission" 2 "Electric Propulsion Control" 1 "Auxiliary Power Unit (APU)" 0 "Engine" 100 "Reserved" 99 "Reserved" 98 "Reserved" 97 "Reserved" 96 "Reserved" 95 "Reserved" 94 "Reserved" 93 "Reserved" 92 "Reserved" 91 "Reserved" 90 "Reserved" 89 "Reserved" 88 "Reserved" 87 "Reserved" 86 "Reserved" 85 "Reserved" 84 "Reserved" 83 "Reserved" 82 "Reserved" 81 "Reserved" 80 "Reserved" 79 "Reserved" 78 "Reserved" 77 "Reserved" 76 "Reserved" 75 "Reserved" 74 "Reserved" 73 "Reserved" 72 "Coolant Valve Controller" 71 "Transfer Case Control" 70 "Auxiliary Regeneration Device" 69 "Engine Emission Aftertreatement System" 68 "Aftertreatment system gas measurement" 67 "Electrical System Controller" 66 "I/O Controller" 65 "Gas Flow Measurement" 64 "Endurance Braking" 63 "Engine Valve Controller" 62 "On-Board Diagnostic Unit" 61 "File Server/Printer" 60 "Cab Display" 59 "Starter" 58 "Fan Drive Control" 57 "Steering Column Unit" 56 "Communications Unit, Radio" 55 "Communications Unit, Satellite" 54 "Communications Unit, Cellular" 53 "Alternator/Charging System" 52 "Chassis Controller" 51 "Forward-Looking Collision Warning System" 50 "Auxiliary Heater" 49 "Clutch/Converter Control" 48 "Ramp Control" 47 "Information System Controller" 46 "Oil Sensor Unit" 45 "Vehicle Dynamic Stability Control" 44 "Exhaust Emission Control" 43 "Transmission Display" ;
VAL_ 2565799452 VehicleSystem1 2 "Trailer" 1 "Tractor" 127 "Not Available" 0 "Non-specific System" ;
VAL_ 2565799452 VehicleSystem2 16 "Skidder" 15 "Earth Work" 14 "Special Crops" 13 "Powered Auxiliary Device" 12 "Farm Yard Operations" 11 "Transport/Trailer" 10 "Irrigation" 9 "Forage" 8 "Root Harvesters" 7 "Harvesters" 6 "Sprayers" 5 "Fertilizers" 4 "Planters/Seeders" 3 "Secondary Tillage" 2 "Tillage" 1 "Tractor" 127 "Not Available" 0 "Non-specific System" ;
VAL_ 2565799452 VehicleSystem3 8 "Grader" 7 "Four Wheel Drive Loader" 6 "Forklift" 5 "Excavator" 4 "Crawler" 3 "Backhoe" 2 "Articulated Dump Truck" 1 "Skid Steer Loader" 127 "Not Available" 0 "Non-specific System" ;
VAL_ 2565799452 VehicleSystem4 100 "Deck/Cargo/Fishing equip. sys" 90 "Environmental (HVAC) Systems" 80 "Instrumentation/General Systems" 70 "Communications Systems" 60 "Navigation Systems" 50 "Propulsion Systems" 40 "Steering Systems" 30 "Power Mgmt and lighting systems" 25 "Gateway" 20 "Safety Systems" 10 "System Tools" 127 "Not Available" 0 "Non-specific System" ;
VAL_ 2565799452 VehicleSystem5 127 "Not Available" 0 "Ind. Process Control Stationary" ;
VAL_ 2565799452 VehicleSystem 0 "Non-specific System" 127 "Not Available" ;
VAL_ 2565799452 IndustryGroup 0 "Global" 1 "OnHighway" 2 "AgriculturalAndForestry" 3 "Construction" 4 "Marine" 5 "Reserved" 7 "NotAvailable" ;
VAL_ 2565406236 ControlByte 3 "CannotRespond" 2 "AccessDenied" 1 "NACK" 0 "ACK" ;
VAL_ evPGN 129029 "GNSS Position Data" 129025 "Position Rapid Update" ;
